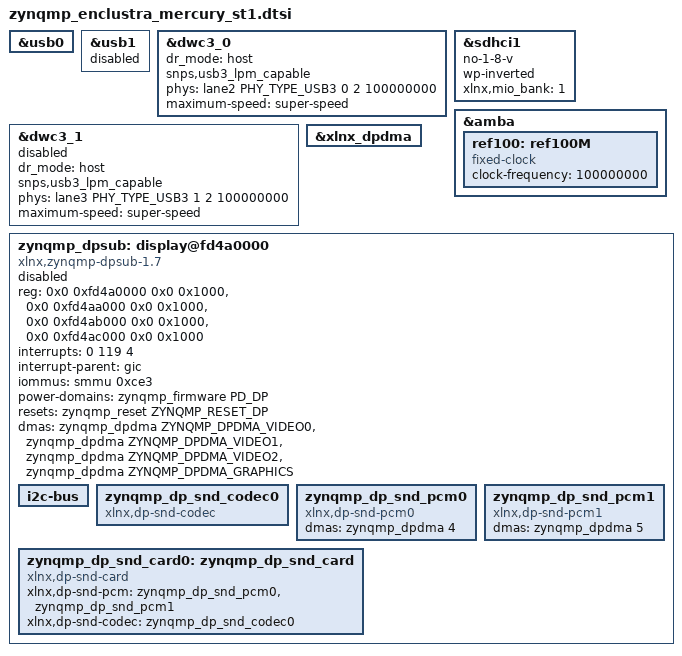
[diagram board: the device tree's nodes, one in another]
#include <dt-bindings/phy/phy.h>

&usb0 {
	status = "okay";
};

&usb1 {
	status = "disabled";
};

&dwc3_0 {
	status = "okay";
	dr_mode = "host";
	snps,usb3_lpm_capable;
	phy-names = "usb3-phy";
	phys = <&lane2 PHY_TYPE_USB3 0 2 100000000>;
	maximum-speed = "super-speed";
};

&dwc3_1 {
	status = "disabled";
	dr_mode = "host";
	snps,usb3_lpm_capable;
	phy-names = "usb3-phy";
	phys = <&lane3 PHY_TYPE_USB3 1 2 100000000>;
	maximum-speed = "super-speed";
};

/* SD1 with level shifter */
&sdhci1 {
	status = "okay";
	no-1-8-v;	/* for 1.0 silicon */
	wp-inverted;
	xlnx,mio_bank = <1>;
};

&amba {
	ref100: ref100M {
		compatible = "fixed-clock";
		#clock-cells = <0>;
		clock-frequency = <100000000>;
	};
};


&xlnx_dpdma {
	status = "okay";
};

zynqmp_dpsub: display@fd4a0000 {
	compatible = "xlnx,zynqmp-dpsub-1.7";
	status = "disabled";
	reg = <0x0 0xfd4a0000 0x0 0x1000>,
		<0x0 0xfd4aa000 0x0 0x1000>,
		<0x0 0xfd4ab000 0x0 0x1000>,
		<0x0 0xfd4ac000 0x0 0x1000>;
	reg-names = "dp", "blend", "av_buf", "aud";
	interrupts = <0 119 4>;
	interrupt-parent = <&gic>;
	#stream-id-cells = <1>;
	iommus = <&smmu 0xce3>;

	clock-names = "dp_apb_clk", "dp_aud_clk",
			"dp_vtc_pixel_clk_in";

	power-domains = <&zynqmp_firmware PD_DP>;
	resets = <&zynqmp_reset ZYNQMP_RESET_DP>;
	dma-names = "vid0", "vid1", "vid2", "gfx0";
	dmas = <&zynqmp_dpdma ZYNQMP_DPDMA_VIDEO0>,
		<&zynqmp_dpdma ZYNQMP_DPDMA_VIDEO1>,
		<&zynqmp_dpdma ZYNQMP_DPDMA_VIDEO2>,
		<&zynqmp_dpdma ZYNQMP_DPDMA_GRAPHICS>;

	/* dummy node to indicate there's no child i2c device */
	i2c-bus {
	};

	zynqmp_dp_snd_codec0: zynqmp_dp_snd_codec0 {
		compatible = "xlnx,dp-snd-codec";
		clock-names = "aud_clk";
	};

	zynqmp_dp_snd_pcm0: zynqmp_dp_snd_pcm0 {
		compatible = "xlnx,dp-snd-pcm0";
		dmas = <&zynqmp_dpdma 4>;
		dma-names = "tx";
	};

	zynqmp_dp_snd_pcm1: zynqmp_dp_snd_pcm1 {
		compatible = "xlnx,dp-snd-pcm1";
		dmas = <&zynqmp_dpdma 5>;
		dma-names = "tx";
	};

	zynqmp_dp_snd_card0: zynqmp_dp_snd_card {
		compatible = "xlnx,dp-snd-card";
		xlnx,dp-snd-pcm = <&zynqmp_dp_snd_pcm0>,
				<&zynqmp_dp_snd_pcm1>;
		xlnx,dp-snd-codec = <&zynqmp_dp_snd_codec0>;
	};
};
